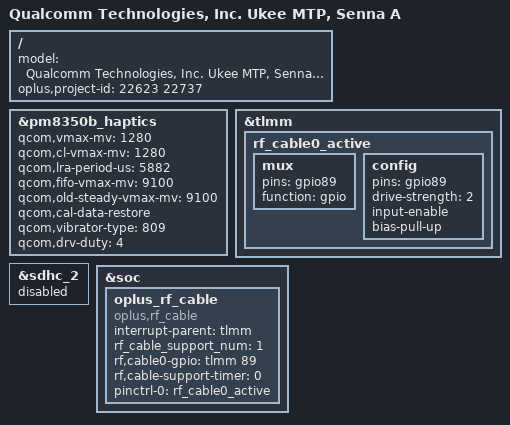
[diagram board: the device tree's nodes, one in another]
/dts-v1/;
/plugin/;
#include <dt-bindings/oplus/hw-id.h>
#include "../qcom/ukee-mtp-pm8010-overlay.dts"
#include "ukee_overlay_common.dtsi"
#include "senna_22623_overlay_common.dtsi"
#include "oplus_uff/oplus_uff_22015.dtsi"
#include "oplus_chg/oplus-chg-22623.dtsi"
#include "nfc/senna-nfc-sn110t.dtsi"
#include "sensor/senna-oplus-sensor.dtsi"
/ {
	model = "Qualcomm Technologies, Inc. Ukee MTP, Senna A";
        oplus,project-id = <22623 22737>;
        //oplus,hw-id = <OPLUS_EVB1 OPLUS_T0 OPLUS_EVT1 OPLUS_EVT2 OPLUS_DVT1 OPLUS_PVT1 OPLUS_MP1>;
};

&pm8350b_haptics {
    qcom,vmax-mv = <1280>;
    qcom,cl-vmax-mv = <1280>;
    qcom,lra-period-us = <5882>;
    qcom,fifo-vmax-mv = <9100>;
    qcom,old-steady-vmax-mv = <9100>;
    qcom,cal-data-restore;
    qcom,vibrator-type = <809>;//ela0809
    qcom,drv-duty = <4>;//75%
};

&tlmm {
  rf_cable0_active: rf_cable0_active {
    mux {
      pins = "gpio89";
      function = "gpio";
    };
    config {
      pins = "gpio89";
      drive-strength = <2>;
      input-enable;
      bias-pull-up;
    };
  };
};

&sdhc_2 {
	status = "disabled";
};

&soc {
  oplus_rf_cable {
    compatible = "oplus,rf_cable";
    interrupt-parent = <&tlmm>;
    rf_cable_support_num = <1>;
    rf,cable0-gpio = <&tlmm 89 0>;
    rf,cable-support-timer = <0>;
    pinctrl-names = "rf_cable_active";
    pinctrl-0 = <&rf_cable0_active>;
  };
};
